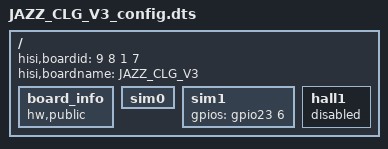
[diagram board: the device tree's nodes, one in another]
/*
 * Hisilicon Ltd.
 *
 * A15x4 A7x4
 *
 * It is only a demo for hisilicon hi3630 board. You show change the
 * address of each node according to datasheet.
 */

/dts-v1/;

/include/ "fastboot.dtsi"
/include/ "JAZZ_CLG_V1_config.dtsi"
/include/ "JAZZ_CLG_V3_pin.dtsi"
/include/ "JAZZ_CLG_V3_modem_pin.dtsi"

/ {
	hisi,boardid = <9 8 1 7>;
	hisi,boardname = "JAZZ_CLG_V3";
	board_info: board_info {
		hw,public;
	};
	sim0 {
		status = "ok";
	};
	sim1 {
		gpios = <&gpio23 6 0>;
		status = "ok";
	};

	hall1 {
		status = "disabled";
	};
};
